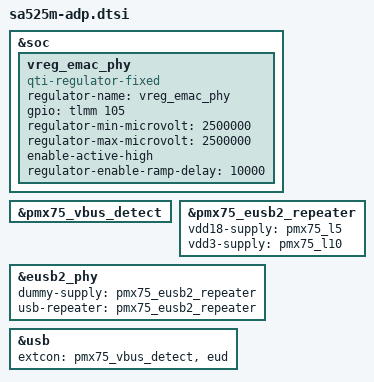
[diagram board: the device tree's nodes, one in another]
// SPDX-License-Identifier: BSD-3-Clause
/*
 * Copyright (c) Qualcomm Technologies, Inc. and/or its subsidiaries.
 */

#include <dt-bindings/gpio/gpio.h>

&soc {
	vreg_emac_phy: vreg_emac_phy {
		compatible = "qti-regulator-fixed";
		regulator-name = "vreg_emac_phy";
		gpio = <&tlmm 105 GPIO_ACTIVE_HIGH>;
		regulator-min-microvolt = <2500000>;
		regulator-max-microvolt = <2500000>;
		enable-active-high;
		regulator-enable-ramp-delay = <10000>;
	};
};

&pmx75_vbus_detect {
	status = "ok";
};

&pmx75_eusb2_repeater {
	vdd18-supply = <&pmx75_l5>;
	vdd3-supply = <&pmx75_l10>;
	status = "ok";
};

&eusb2_phy {
	dummy-supply = <&pmx75_eusb2_repeater>;
	usb-repeater = <&pmx75_eusb2_repeater>;
};

&usb {
	extcon = <&pmx75_vbus_detect>, <&eud>;
};
